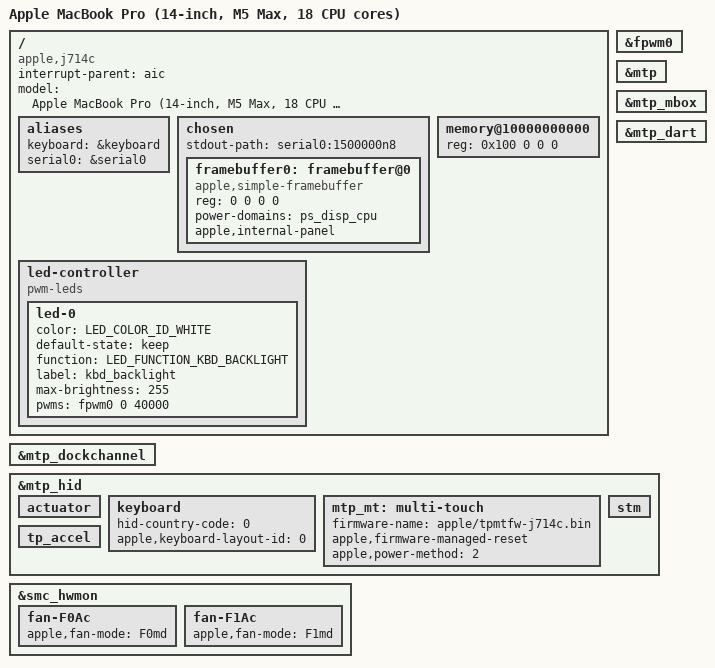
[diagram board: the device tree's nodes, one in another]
// SPDX-License-Identifier: GPL-2.0+ OR MIT
/*
 * Apple MacBook Pro (14-inch, M5 Max, 18 CPU cores)
 *
 * target-type: J714c
 *
 * The loader supplies usable memory, CPU release addresses and
 * framebuffer geometry. Peripheral power domains come from
 * t6050-pmgr.dtsi; the framebuffer holds the display domain.
 *
 * Copyright The Asahi Linux Contributors
 */

/dts-v1/;

#include <dt-bindings/interrupt-controller/apple-aic.h>
#include <dt-bindings/interrupt-controller/irq.h>
#include <dt-bindings/leds/common.h>

#include "t6050.dtsi"
#include "t6050-smc.dtsi"
#include "t6050-j714c-isp.dtsi"

/ {
	compatible = "apple,j714c", "apple,t6050", "apple,arm-platform";
	#address-cells = <2>;
	interrupt-parent = <&aic>;
	model = "Apple MacBook Pro (14-inch, M5 Max, 18 CPU cores)";
	#size-cells = <2>;

	aliases {
		keyboard = &keyboard;
		serial0 = &serial0;
	};

	chosen {
		ranges;
		#address-cells = <2>;
		#size-cells = <2>;
		stdout-path = "serial0:1500000n8";

		framebuffer0: framebuffer@0 {
			compatible = "apple,simple-framebuffer", "simple-framebuffer";
			reg = <0 0 0 0>; /* Filled by the loader. */
			power-domains = <&ps_disp_cpu>;
			apple,internal-panel; /* simpledrm reports it as eDP */

			status = "okay"; /* m1n1 only enables it on chips it knows. */
		};
	};

	memory@10000000000 {
		reg = <0x100 0 0 0>; /* Filled by the loader. */
		device_type = "memory";
	};

	led-controller {
		compatible = "pwm-leds";

		led-0 {
			color = <LED_COLOR_ID_WHITE>;
			default-state = "keep";
			function = LED_FUNCTION_KBD_BACKLIGHT;
			label = "kbd_backlight";
			max-brightness = <255>;
			pwms = <&fpwm0 0 40000>;
		};
	};
};

&fpwm0 {
	status = "okay";
};

&mtp {
	status = "okay";
};

&mtp_mbox {
	status = "okay";
};

&mtp_dart {
	status = "okay";
};

&mtp_dockchannel {
	status = "okay";
};

&mtp_hid {
	actuator {
	};

	keyboard: keyboard {
		hid-country-code = <0>;
		apple,keyboard-layout-id = <0>;
	};

	mtp_mt: multi-touch {
		firmware-name = "apple/tpmtfw-j714c.bin";
		apple,firmware-managed-reset;
		apple,power-method = <2>;
	};

	stm {
	};

	tp_accel {
	};
};

#include "hwmon-common.dtsi"
#include "hwmon-fan-dual.dtsi"
#include "hwmon-laptop.dtsi"

/*
 * The T6050 SMC spells the fan mode keys F0md/F1md; F0Md/F1Md from
 * hwmon-fan*.dtsi do not exist.
 */
&smc_hwmon {
	fan-F0Ac {
		apple,fan-mode = "F0md";
	};

	fan-F1Ac {
		apple,fan-mode = "F1md";
	};
};
